# PRM_RTC register map
Vendor: Texas Instruments
Peripheral module from a debugger description file (folder am335x).
Registers are 32-bit, access per field, no defined reset value unless marked. A register's access mark holds for its fields unless they carry their own. Offsets are as the file gives them; lines under a group give offsets from that group; [hi:lo] are bit positions; {n}, {i} and the like mark numbered series; 'fields as' and 'values as' point back to an identical list; <NAME> marks a mode.

## PRM_RTC
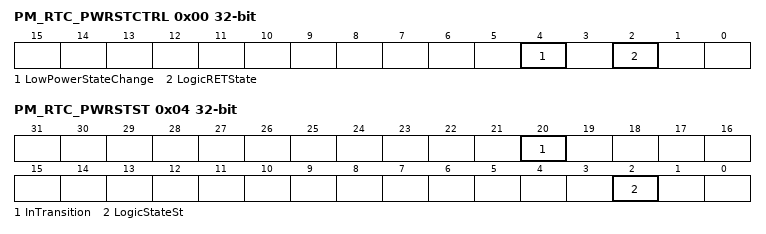
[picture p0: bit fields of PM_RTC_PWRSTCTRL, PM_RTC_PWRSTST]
0x00 PM_RTC_PWRSTCTRL — This register controls the RTC power state to reach upon mpu domain sleep transition
  [4] LowPowerStateChange rw — Power state change request when domain has already performed a sleep transition. Allows going into deeper low power state without waking up the power domain.
    0=DIS (Do not request a low power state change.); 1=EN (Request a low power state change. This bit is automatically cleared when the power state is effectively changed or when power state is ON.)
  [2] LogicRETState rw — Logic state when power domain is RETENTION
    0=logic_off (Only retention registers are retained and remaing logic is off when the domain is in RETENTION state.); 1=logic_ret (Whole logic is retained when domain is in RETENTION state.)
0x04 PM_RTC_PWRSTST ro — This register provides a status on the current RTC power domain state0. [warm reset insensitive]
  [20] InTransition — Domain transition status
    0=No (No on-going transition on power domain); 1=Ongoing (Power domain transition is in progress.)
  [2] LogicStateSt — Logic state status
    0=OFF (Logic in domain is OFF); 1=ON (Logic in domain is ON)
